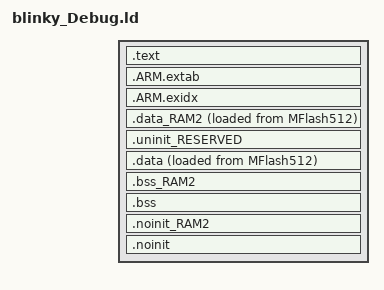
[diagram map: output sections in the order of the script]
/*
 * GENERATED FILE - DO NOT EDIT
 * Copyright (c) 2008-2013 Code Red Technologies Ltd,
 * Copyright 2015, 2018-2019 NXP
 * (c) NXP Semiconductors 2013-2023
 * Generated linker script file for LPC1768
 * Created from linkscript.ldt by FMCreateLinkLibraries
 * Using Freemarker v2.3.30
 * MCUXpresso IDE v11.7.1 [Build 9221] [2023-03-28] on Jun 22, 2023, 9:49:02 AM
 */

INCLUDE "blinky_Debug_library.ld"
INCLUDE "blinky_Debug_memory.ld"

ENTRY(ResetISR)

SECTIONS
{
     /* MAIN TEXT SECTION */
    .text : ALIGN(4)
    {
        FILL(0xff)
        __vectors_start__ = ABSOLUTE(.) ;
        KEEP(*(.isr_vector))
        /* Global Section Table */
        . = ALIGN(4) ;
        __section_table_start = .;
        __data_section_table = .;
        LONG(LOADADDR(.data));
        LONG(    ADDR(.data));
        LONG(  SIZEOF(.data));
        LONG(LOADADDR(.data_RAM2));
        LONG(    ADDR(.data_RAM2));
        LONG(  SIZEOF(.data_RAM2));
        __data_section_table_end = .;
        __bss_section_table = .;
        LONG(    ADDR(.bss));
        LONG(  SIZEOF(.bss));
        LONG(    ADDR(.bss_RAM2));
        LONG(  SIZEOF(.bss_RAM2));
        __bss_section_table_end = .;
        __section_table_end = . ;
        /* End of Global Section Table */

        *(.after_vectors*)

        /* Code Read Protection data */
        . = 0x000002FC ;
        PROVIDE(__CRP_WORD_START__ = .) ;
        KEEP(*(.crp))
        PROVIDE(__CRP_WORD_END__ = .) ;
        ASSERT(!(__CRP_WORD_START__ == __CRP_WORD_END__), "Linker CRP Enabled, but no CRP_WORD provided within application");
        /* End of Code Read Protection */
       *(.text*)
       *(.rodata .rodata.* .constdata .constdata.*)
       . = ALIGN(4);
            /* C++ constructors etc */
            . = ALIGN(4);
            KEEP(*(.init))
            
            . = ALIGN(4);
            __preinit_array_start = .;
            KEEP (*(.preinit_array))
            __preinit_array_end = .;
            
            . = ALIGN(4);
            __init_array_start = .;
            KEEP (*(SORT(.init_array.*)))
            KEEP (*(.init_array))
            __init_array_end = .;
            
            KEEP(*(.fini));
            
            . = ALIGN(4);
            KEEP (*crtbegin.o(.ctors))
            KEEP (*(EXCLUDE_FILE (*crtend.o) .ctors))
            KEEP (*(SORT(.ctors.*)))
            KEEP (*crtend.o(.ctors))
            
            . = ALIGN(4);
            KEEP (*crtbegin.o(.dtors))
            KEEP (*(EXCLUDE_FILE (*crtend.o) .dtors))
            KEEP (*(SORT(.dtors.*)))
            KEEP (*crtend.o(.dtors))
            . = ALIGN(4);
            /* End C++ */
    } > MFlash512
    /*
     * for exception handling/unwind - some Newlib functions (in common
     * with C++ and STDC++) use this.
     */
    .ARM.extab : ALIGN(4)
    {
        *(.ARM.extab* .gnu.linkonce.armextab.*)
    } > MFlash512

    .ARM.exidx : ALIGN(4)
    {
        __exidx_start = .;
        *(.ARM.exidx* .gnu.linkonce.armexidx.*)
        __exidx_end = .;
    } > MFlash512
 
    _etext = .;
        
    /* DATA section for RamAHB32 */

    .data_RAM2 : ALIGN(4)
    {
        FILL(0xff)
        PROVIDE(__start_data_RAM2 = .) ;
        PROVIDE(__start_data_RamAHB32 = .) ;
        *(.ramfunc.$RAM2)
        *(.ramfunc.$RamAHB32)
        *(.data.$RAM2)
        *(.data.$RamAHB32)
        *(.data.$RAM2.*)
        *(.data.$RamAHB32.*)
        . = ALIGN(4) ;
        PROVIDE(__end_data_RAM2 = .) ;
        PROVIDE(__end_data_RamAHB32 = .) ;
     } > RamAHB32 AT>MFlash512

    /* MAIN DATA SECTION */
    .uninit_RESERVED (NOLOAD) : ALIGN(4)
    {
        _start_uninit_RESERVED = .;
        KEEP(*(.bss.$RESERVED*))
       . = ALIGN(4) ;
        _end_uninit_RESERVED = .;
    } > RamLoc32 AT> RamLoc32

    /* Main DATA section (RamLoc32) */
    .data : ALIGN(4)
    {
       FILL(0xff)
       _data = . ;
       PROVIDE(__start_data_RAM = .) ;
       PROVIDE(__start_data_RamLoc32 = .) ;
       *(vtable)
       *(.ramfunc*)
       KEEP(*(CodeQuickAccess))
       KEEP(*(DataQuickAccess))
       *(RamFunction)
       *(.data*)
       . = ALIGN(4) ;
       _edata = . ;
       PROVIDE(__end_data_RAM = .) ;
       PROVIDE(__end_data_RamLoc32 = .) ;
    } > RamLoc32 AT>MFlash512

    /* BSS section for RamAHB32 */
    .bss_RAM2 : ALIGN(4)
    {
       PROVIDE(__start_bss_RAM2 = .) ;
       PROVIDE(__start_bss_RamAHB32 = .) ;
       *(.bss.$RAM2)
       *(.bss.$RamAHB32)
       *(.bss.$RAM2.*)
       *(.bss.$RamAHB32.*)
       . = ALIGN (. != 0 ? 4 : 1) ; /* avoid empty segment */
       PROVIDE(__end_bss_RAM2 = .) ;
       PROVIDE(__end_bss_RamAHB32 = .) ;
    } > RamAHB32 AT> RamAHB32

    /* MAIN BSS SECTION */
    .bss : ALIGN(4)
    {
        _bss = .;
        PROVIDE(__start_bss_RAM = .) ;
        PROVIDE(__start_bss_RamLoc32 = .) ;
        *(.bss*)
        *(COMMON)
        . = ALIGN(4) ;
        _ebss = .;
        PROVIDE(__end_bss_RAM = .) ;
        PROVIDE(__end_bss_RamLoc32 = .) ;
        PROVIDE(end = .);
    } > RamLoc32 AT> RamLoc32

    /* NOINIT section for RamAHB32 */
    .noinit_RAM2 (NOLOAD) : ALIGN(4)
    {
       PROVIDE(__start_noinit_RAM2 = .) ;
       PROVIDE(__start_noinit_RamAHB32 = .) ;
       *(.noinit.$RAM2)
       *(.noinit.$RamAHB32)
       *(.noinit.$RAM2.*)
       *(.noinit.$RamAHB32.*)
       . = ALIGN(4) ;
       PROVIDE(__end_noinit_RAM2 = .) ;
       PROVIDE(__end_noinit_RamAHB32 = .) ;
    } > RamAHB32 AT> RamAHB32

    /* DEFAULT NOINIT SECTION */
    .noinit (NOLOAD): ALIGN(4)
    {
        _noinit = .;
        PROVIDE(__start_noinit_RAM = .) ;
        PROVIDE(__start_noinit_RamLoc32 = .) ;
        *(.noinit*)
         . = ALIGN(4) ;
        _end_noinit = .;
       PROVIDE(__end_noinit_RAM = .) ;
       PROVIDE(__end_noinit_RamLoc32 = .) ;        
    } > RamLoc32 AT> RamLoc32

    PROVIDE(_pvHeapStart = DEFINED(__user_heap_base) ? __user_heap_base : .);

    PROVIDE(_vStackTop = DEFINED(__user_stack_top) ? __user_stack_top : __top_RamLoc32 - 0);

    /* ## Create checksum value (used in startup) ## */
    PROVIDE(__valid_user_code_checksum = 0 - 
                                         (_vStackTop 
                                         + (ResetISR + 1) 
                                         + (NMI_Handler + 1) 
                                         + (HardFault_Handler + 1) 
                                         + (( DEFINED(MemManage_Handler) ? MemManage_Handler : 0 ) + 1)   /* MemManage_Handler may not be defined */
                                         + (( DEFINED(BusFault_Handler) ? BusFault_Handler : 0 ) + 1)     /* BusFault_Handler may not be defined */
                                         + (( DEFINED(UsageFault_Handler) ? UsageFault_Handler : 0 ) + 1) /* UsageFault_Handler may not be defined */
                                         ) );

    /* Provide basic symbols giving location and size of main text
     * block, including initial values of RW data sections. Note that
     * these will need extending to give a complete picture with
     * complex images (e.g multiple Flash banks).
     */
    _image_start = LOADADDR(.text);
    _image_end = LOADADDR(.data) + SIZEOF(.data);
    _image_size = _image_end - _image_start;
}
